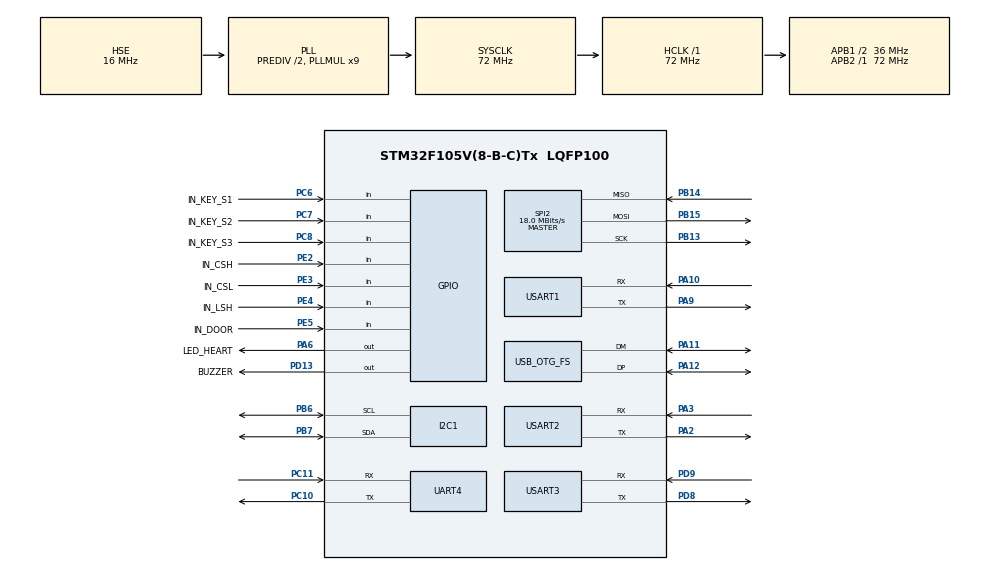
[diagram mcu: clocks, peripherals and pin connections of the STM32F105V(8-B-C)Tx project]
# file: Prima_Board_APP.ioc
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FREERTOS.Tasks01=defaultTask,0,128,StartDefaultTask,Default,NULL,Dynamic,NULL,NULL
FREERTOS.configUSE_NEWLIB_REENTRANT=1
Mcu.Family=STM32F1
Mcu.Name=STM32F105V(8-B-C)Tx
Mcu.Package=LQFP100
NVIC.PriorityGroup=NVIC_PRIORITYGROUP_4
NVIC.TIM6_IRQn=true\:15\:0\:false\:false\:true\:false\:false\:true\:true
NVIC.TimeBase=TIM6_IRQn
NVIC.TimeBaseIP=TIM6
OSC_IN.Mode=HSE-External-Oscillator
OSC_IN.Signal=RCC_OSC_IN
OSC_OUT.Mode=HSE-External-Oscillator
OSC_OUT.Signal=RCC_OSC_OUT
PA10.Mode=Asynchronous
PA10.Signal=USART1_RX
PA11.Mode=Host_Only
PA11.Signal=USB_OTG_FS_DM
PA12.Mode=Host_Only
PA12.Signal=USB_OTG_FS_DP
PA13.Mode=Serial_Wire
PA13.Signal=SYS_JTMS-SWDIO
PA14.Mode=Serial_Wire
PA14.Signal=SYS_JTCK-SWCLK
PA2.Mode=Asynchronous
PA2.Signal=USART2_TX
PA3.Mode=Asynchronous
PA3.Signal=USART2_RX
PA6.GPIO_Label=LED_HEART
PA6.Signal=GPIO_Output
PA9.Mode=Asynchronous
PA9.Signal=USART1_TX
PB13.Mode=Full_Duplex_Master
PB13.Signal=SPI2_SCK
PB14.Mode=Full_Duplex_Master
PB14.Signal=SPI2_MISO
PB15.Mode=Full_Duplex_Master
PB15.Signal=SPI2_MOSI
PB6.Mode=I2C
PB6.Signal=I2C1_SCL
PB7.Mode=I2C
PB7.Signal=I2C1_SDA
PC10.Mode=Asynchronous
PC10.Signal=UART4_TX
PC11.Mode=Asynchronous
PC11.Signal=UART4_RX
PC6.GPIO_Label=IN_KEY_S1
PC6.Signal=GPIO_Input
PC7.GPIO_Label=IN_KEY_S2
PC7.Signal=GPIO_Input
PC8.GPIO_Label=IN_KEY_S3
PC8.Signal=GPIO_Input
PD13.GPIO_Label=BUZZER
PD13.Signal=GPIO_Output
PD8.Mode=Asynchronous
PD8.Signal=USART3_TX
PD9.Mode=Asynchronous
PD9.Signal=USART3_RX
PE2.GPIO_Label=IN_CSH
PE2.Signal=GPIO_Input
PE3.GPIO_Label=IN_CSL
PE3.Signal=GPIO_Input
PE4.GPIO_Label=IN_LSH
PE4.Signal=GPIO_Input
PE5.GPIO_Label=IN_DOOR
PE5.Signal=GPIO_Input
ProjectManager.HeapSize=0x200
ProjectManager.StackSize=0x400
ProjectManager.TargetToolchain=STM32CubeIDE
RCC.AHBFreq_Value=72000000
RCC.APB1CLKDivider=RCC_HCLK_DIV2
RCC.APB1Freq_Value=36000000
RCC.APB1TimFreq_Value=72000000
RCC.APB2Freq_Value=72000000
RCC.APB2TimFreq_Value=72000000
RCC.HCLKFreq_Value=72000000
RCC.HSEDivPLL=RCC_HSE_PREDIV_DIV2
RCC.HSE_VALUE=16000000
RCC.PLLMUL=RCC_PLL_MUL9
RCC.PLLSourceVirtual=RCC_PLLSOURCE_HSE
RCC.SYSCLKFreq_VALUE=72000000
RCC.SYSCLKSource=RCC_SYSCLKSOURCE_PLLCLK
RCC.USBFreq_Value=48000000
SPI2.CalculateBaudRate=18.0 MBits/s
SPI2.Direction=SPI_DIRECTION_2LINES
SPI2.Mode=SPI_MODE_MASTER
SPI2.VirtualType=VM_MASTER
UART4.VirtualMode=Asynchronous
USART1.VirtualMode=VM_ASYNC
USART2.VirtualMode=VM_ASYNC
USART3.VirtualMode=VM_ASYNC
USB_OTG_FS.VirtualMode=Host_Only
VP_FREERTOS_VS_CMSIS_V1.Mode=CMSIS_V1
VP_SYS_VS_tim6.Mode=TIM6
board=custom

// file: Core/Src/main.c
/* USER CODE BEGIN Header */
/**
  ******************************************************************************
  * @file           : main.c
  * @brief          : Main program body
  ******************************************************************************
  * @attention
  *
  * Copyright (c) 2022 STMicroelectronics.
  * All rights reserved.
  *
  * This software is licensed under terms that can be found in the LICENSE file
  * in the root directory of this software component.
  * If no LICENSE file comes with this software, it is provided AS-IS.
  *
  ******************************************************************************
  */
/* USER CODE END Header */
#include "main.h"
#include "cmsis_os.h"

I2C_HandleTypeDef hi2c1;

SPI_HandleTypeDef hspi2;

UART_HandleTypeDef huart4;
UART_HandleTypeDef huart1;
UART_HandleTypeDef huart2;
UART_HandleTypeDef huart3;

HCD_HandleTypeDef hhcd_USB_OTG_FS;

osThreadId defaultTaskHandle;

void SystemClock_Config(void);
static void MX_GPIO_Init(void);
static void MX_UART4_Init(void);
static void MX_USART1_UART_Init(void);
static void MX_USART2_UART_Init(void);
static void MX_USART3_UART_Init(void);
static void MX_I2C1_Init(void);
static void MX_SPI2_Init(void);
static void MX_USB_OTG_FS_HCD_Init(void);
void StartDefaultTask(void const * argument);

int main(void)
{

  /* MCU Configuration--------------------------------------------------------*/

  /* Reset of all peripherals, Initializes the Flash interface and the Systick. */
  HAL_Init();

  /* Configure the system clock */
  SystemClock_Config();

  /* Initialize all configured peripherals */
  MX_GPIO_Init();
  MX_UART4_Init();
  MX_USART1_UART_Init();
  MX_USART2_UART_Init();
  MX_USART3_UART_Init();
  MX_I2C1_Init();
  MX_SPI2_Init();
  MX_USB_OTG_FS_HCD_Init();

  /* Create the thread(s) */
  /* definition and creation of defaultTask */
  osThreadDef(defaultTask, StartDefaultTask, osPriorityNormal, 0, 128);
  defaultTaskHandle = osThreadCreate(osThread(defaultTask), NULL);

  /* Start scheduler */
  osKernelStart();

  /* We should never get here as control is now taken by the scheduler */
  /* Infinite loop */
  while (1)
  {

  }
}

void SystemClock_Config(void)
{
  RCC_OscInitTypeDef RCC_OscInitStruct = {0};
  RCC_ClkInitTypeDef RCC_ClkInitStruct = {0};
  RCC_PeriphCLKInitTypeDef PeriphClkInit = {0};

  /** Initializes the RCC Oscillators according to the specified parameters
  * in the RCC_OscInitTypeDef structure.
  */
  RCC_OscInitStruct.OscillatorType = RCC_OSCILLATORTYPE_HSE;
  RCC_OscInitStruct.HSEState = RCC_HSE_ON;
  RCC_OscInitStruct.HSEPredivValue = RCC_HSE_PREDIV_DIV2;
  RCC_OscInitStruct.HSIState = RCC_HSI_ON;
  RCC_OscInitStruct.Prediv1Source = RCC_PREDIV1_SOURCE_HSE;
  RCC_OscInitStruct.PLL.PLLState = RCC_PLL_ON;
  RCC_OscInitStruct.PLL.PLLSource = RCC_PLLSOURCE_HSE;
  RCC_OscInitStruct.PLL.PLLMUL = RCC_PLL_MUL9;
  RCC_OscInitStruct.PLL2.PLL2State = RCC_PLL_NONE;
  if (HAL_RCC_OscConfig(&RCC_OscInitStruct) != HAL_OK)
  {
    Error_Handler();
  }

  /** Initializes the CPU, AHB and APB buses clocks
  */
  RCC_ClkInitStruct.ClockType = RCC_CLOCKTYPE_HCLK|RCC_CLOCKTYPE_SYSCLK
                              |RCC_CLOCKTYPE_PCLK1|RCC_CLOCKTYPE_PCLK2;
  RCC_ClkInitStruct.SYSCLKSource = RCC_SYSCLKSOURCE_PLLCLK;
  RCC_ClkInitStruct.AHBCLKDivider = RCC_SYSCLK_DIV1;
  RCC_ClkInitStruct.APB1CLKDivider = RCC_HCLK_DIV2;
  RCC_ClkInitStruct.APB2CLKDivider = RCC_HCLK_DIV1;

  if (HAL_RCC_ClockConfig(&RCC_ClkInitStruct, FLASH_LATENCY_2) != HAL_OK)
  {
    Error_Handler();
  }
  PeriphClkInit.PeriphClockSelection = RCC_PERIPHCLK_USB;
  PeriphClkInit.UsbClockSelection = RCC_USBCLKSOURCE_PLL_DIV3;
  if (HAL_RCCEx_PeriphCLKConfig(&PeriphClkInit) != HAL_OK)
  {
    Error_Handler();
  }

  /** Configure the Systick interrupt time
  */
  __HAL_RCC_PLLI2S_ENABLE();
}

static void MX_I2C1_Init(void)
{

  hi2c1.Instance = I2C1;
  hi2c1.Init.ClockSpeed = 100000;
  hi2c1.Init.DutyCycle = I2C_DUTYCYCLE_2;
  hi2c1.Init.OwnAddress1 = 0;
  hi2c1.Init.AddressingMode = I2C_ADDRESSINGMODE_7BIT;
  hi2c1.Init.DualAddressMode = I2C_DUALADDRESS_DISABLE;
  hi2c1.Init.OwnAddress2 = 0;
  hi2c1.Init.GeneralCallMode = I2C_GENERALCALL_DISABLE;
  hi2c1.Init.NoStretchMode = I2C_NOSTRETCH_DISABLE;
  if (HAL_I2C_Init(&hi2c1) != HAL_OK)
  {
    Error_Handler();
  }

}

static void MX_SPI2_Init(void)
{

  /* SPI2 parameter configuration*/
  hspi2.Instance = SPI2;
  hspi2.Init.Mode = SPI_MODE_MASTER;
  hspi2.Init.Direction = SPI_DIRECTION_2LINES;
  hspi2.Init.DataSize = SPI_DATASIZE_8BIT;
  hspi2.Init.CLKPolarity = SPI_POLARITY_LOW;
  hspi2.Init.CLKPhase = SPI_PHASE_1EDGE;
  hspi2.Init.NSS = SPI_NSS_SOFT;
  hspi2.Init.BaudRatePrescaler = SPI_BAUDRATEPRESCALER_2;
  hspi2.Init.FirstBit = SPI_FIRSTBIT_MSB;
  hspi2.Init.TIMode = SPI_TIMODE_DISABLE;
  hspi2.Init.CRCCalculation = SPI_CRCCALCULATION_DISABLE;
  hspi2.Init.CRCPolynomial = 10;
  if (HAL_SPI_Init(&hspi2) != HAL_OK)
  {
    Error_Handler();
  }

}

static void MX_UART4_Init(void)
{

  huart4.Instance = UART4;
  huart4.Init.BaudRate = 115200;
  huart4.Init.WordLength = UART_WORDLENGTH_8B;
  huart4.Init.StopBits = UART_STOPBITS_1;
  huart4.Init.Parity = UART_PARITY_NONE;
  huart4.Init.Mode = UART_MODE_TX_RX;
  huart4.Init.HwFlowCtl = UART_HWCONTROL_NONE;
  huart4.Init.OverSampling = UART_OVERSAMPLING_16;
  if (HAL_UART_Init(&huart4) != HAL_OK)
  {
    Error_Handler();
  }

}

static void MX_USART1_UART_Init(void)
{

  huart1.Instance = USART1;
  huart1.Init.BaudRate = 115200;
  huart1.Init.WordLength = UART_WORDLENGTH_8B;
  huart1.Init.StopBits = UART_STOPBITS_1;
  huart1.Init.Parity = UART_PARITY_NONE;
  huart1.Init.Mode = UART_MODE_TX_RX;
  huart1.Init.HwFlowCtl = UART_HWCONTROL_NONE;
  huart1.Init.OverSampling = UART_OVERSAMPLING_16;
  if (HAL_UART_Init(&huart1) != HAL_OK)
  {
    Error_Handler();
  }

}

static void MX_USART2_UART_Init(void)
{

  huart2.Instance = USART2;
  huart2.Init.BaudRate = 115200;
  huart2.Init.WordLength = UART_WORDLENGTH_8B;
  huart2.Init.StopBits = UART_STOPBITS_1;
  huart2.Init.Parity = UART_PARITY_NONE;
  huart2.Init.Mode = UART_MODE_TX_RX;
  huart2.Init.HwFlowCtl = UART_HWCONTROL_NONE;
  huart2.Init.OverSampling = UART_OVERSAMPLING_16;
  if (HAL_UART_Init(&huart2) != HAL_OK)
  {
    Error_Handler();
  }

}

static void MX_USART3_UART_Init(void)
{

  huart3.Instance = USART3;
  huart3.Init.BaudRate = 115200;
  huart3.Init.WordLength = UART_WORDLENGTH_8B;
  huart3.Init.StopBits = UART_STOPBITS_1;
  huart3.Init.Parity = UART_PARITY_NONE;
  huart3.Init.Mode = UART_MODE_TX_RX;
  huart3.Init.HwFlowCtl = UART_HWCONTROL_NONE;
  huart3.Init.OverSampling = UART_OVERSAMPLING_16;
  if (HAL_UART_Init(&huart3) != HAL_OK)
  {
    Error_Handler();
  }

}

static void MX_USB_OTG_FS_HCD_Init(void)
{

  hhcd_USB_OTG_FS.Instance = USB_OTG_FS;
  hhcd_USB_OTG_FS.Init.Host_channels = 8;
  hhcd_USB_OTG_FS.Init.speed = HCD_SPEED_FULL;
  hhcd_USB_OTG_FS.Init.phy_itface = HCD_PHY_EMBEDDED;
  hhcd_USB_OTG_FS.Init.Sof_enable = DISABLE;
  if (HAL_HCD_Init(&hhcd_USB_OTG_FS) != HAL_OK)
  {
    Error_Handler();
  }

}

static void MX_GPIO_Init(void)
{
  GPIO_InitTypeDef GPIO_InitStruct = {0};

  /* GPIO Ports Clock Enable */
  __HAL_RCC_GPIOE_CLK_ENABLE();
  __HAL_RCC_GPIOA_CLK_ENABLE();
  __HAL_RCC_GPIOB_CLK_ENABLE();
  __HAL_RCC_GPIOD_CLK_ENABLE();
  __HAL_RCC_GPIOC_CLK_ENABLE();

  /*Configure GPIO pin Output Level */
  HAL_GPIO_WritePin(LED_HEART_GPIO_Port, LED_HEART_Pin, GPIO_PIN_RESET);

  /*Configure GPIO pin Output Level */
  HAL_GPIO_WritePin(BUZZER_GPIO_Port, BUZZER_Pin, GPIO_PIN_RESET);

  /*Configure GPIO pins : IN_CSH_Pin IN_CSL_Pin IN_LSH_Pin IN_DOOR_Pin */
  GPIO_InitStruct.Pin = IN_CSH_Pin|IN_CSL_Pin|IN_LSH_Pin|IN_DOOR_Pin;
  GPIO_InitStruct.Mode = GPIO_MODE_INPUT;
  GPIO_InitStruct.Pull = GPIO_NOPULL;
  HAL_GPIO_Init(GPIOE, &GPIO_InitStruct);

  /*Configure GPIO pin : LED_HEART_Pin */
  GPIO_InitStruct.Pin = LED_HEART_Pin;
  GPIO_InitStruct.Mode = GPIO_MODE_OUTPUT_PP;
  GPIO_InitStruct.Pull = GPIO_NOPULL;
  GPIO_InitStruct.Speed = GPIO_SPEED_FREQ_LOW;
  HAL_GPIO_Init(LED_HEART_GPIO_Port, &GPIO_InitStruct);

  /*Configure GPIO pin : BUZZER_Pin */
  GPIO_InitStruct.Pin = BUZZER_Pin;
  GPIO_InitStruct.Mode = GPIO_MODE_OUTPUT_PP;
  GPIO_InitStruct.Pull = GPIO_NOPULL;
  GPIO_InitStruct.Speed = GPIO_SPEED_FREQ_LOW;
  HAL_GPIO_Init(BUZZER_GPIO_Port, &GPIO_InitStruct);

  /*Configure GPIO pins : IN_KEY_S1_Pin IN_KEY_S2_Pin IN_KEY_S3_Pin */
  GPIO_InitStruct.Pin = IN_KEY_S1_Pin|IN_KEY_S2_Pin|IN_KEY_S3_Pin;
  GPIO_InitStruct.Mode = GPIO_MODE_INPUT;
  GPIO_InitStruct.Pull = GPIO_NOPULL;
  HAL_GPIO_Init(GPIOC, &GPIO_InitStruct);

}

void StartDefaultTask(void const * argument)
{
  /* USER CODE BEGIN 5 */
  /* Infinite loop */

  for(;;)
  {
	HAL_GPIO_TogglePin(LED_HEART_GPIO_Port, LED_HEART_Pin);
    osDelay(200);
  }
  /* USER CODE END 5 */
}

void HAL_TIM_PeriodElapsedCallback(TIM_HandleTypeDef *htim)
{
  if (htim->Instance == TIM6) {
    HAL_IncTick();
  }
}

void Error_Handler(void)
{
  __disable_irq();
  while (1)
  {
  }
}
